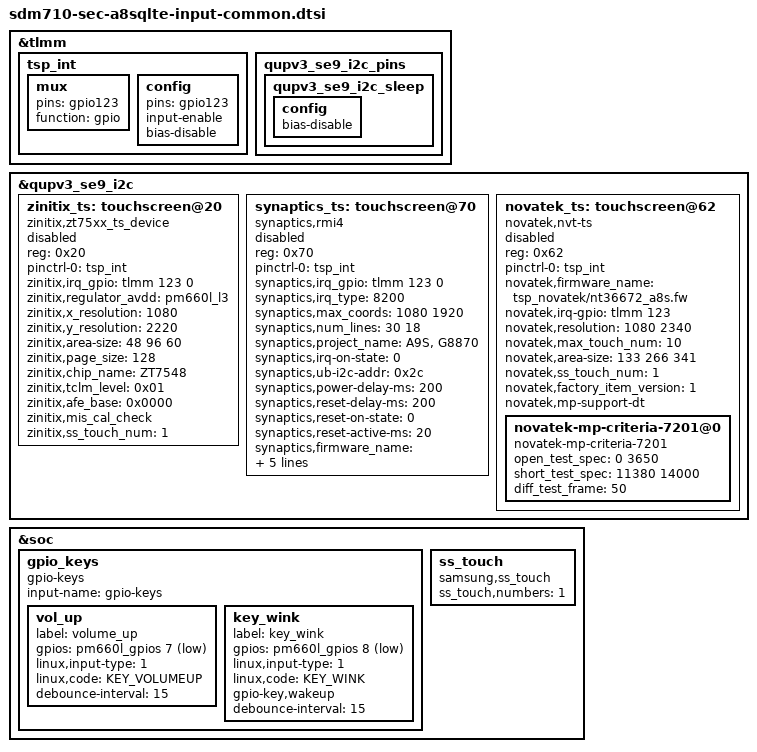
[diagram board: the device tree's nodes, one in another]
/* Copyright (c) 2016-2017, The Linux Foundation. All rights reserved.
 *
 * This program is free software; you can redistribute it and/or modify
 * it under the terms of the GNU General Public License version 2 and
 * only version 2 as published by the Free Software Foundation.
 *
 * This program is distributed in the hope that it will be useful,
 * but WITHOUT ANY WARRANTY; without even the implied warranty of
 * MERCHANTABILITY or FITNESS FOR A PARTICULAR PURPOSE.  See the
 * GNU General Public License for more details.
 */

#include <dt-bindings/input/input.h>

&tlmm {
	tsp_int: tsp_int {
		mux {
			pins = "gpio123";
			function = "gpio";
		};

		config {
			pins = "gpio123";
			input-enable;
			bias-disable;
		};
	};

	qupv3_se9_i2c_pins {
		qupv3_se9_i2c_sleep {
			config {
				/delete-property/bias-pull-up;
				bias-disable;
			};
		};
	};
};

&qupv3_se9_i2c {
	status = "ok";

	zinitix_ts: touchscreen@20 {
		status = "disabled";
		compatible = "zinitix,zt75xx_ts_device";
		reg = <0x20>;
		pinctrl-names = "default";
		pinctrl-0 = <&tsp_int>;
		zinitix,irq_gpio = <&tlmm 123 0>;
	/*	zinitix,gpio_ldo_en;*/
	/*	zinitix,regulator_dvdd = "s2mpb02_sub-ldo5";*/
		zinitix,regulator_avdd = "pm660l_l3";
		zinitix,x_resolution = <1080>;
		zinitix,y_resolution = <2220>;
		zinitix,area-size = <48 96 60>; /* indicator: 24dp navigator:48dp edge:60px dpi=320 */
		zinitix,page_size = <128>;
		zinitix,chip_name = "ZT7548";
	/*	zinitix,firmware_name = "tsp_zinitix/zt7548_astar.fw"; */
	/*	zinitix,spay;*/
	/*	zinitix,aod;*/
		zinitix,tclm_level = <0x01>;
		zinitix,afe_base = <0x0000>;
		zinitix,mis_cal_check;
	/*	zinitix,factory_item_version = <4>;*/
		zinitix,ss_touch_num = <1>;
	};

	synaptics_ts: touchscreen@70 {
		status = "disabled";
		compatible = "synaptics,rmi4";
		reg = <0x70>;
		pinctrl-names = "default";
		pinctrl-0 = <&tsp_int>;
		synaptics,irq_gpio = <&tlmm 123 0>;
		synaptics,irq_type = <8200>;
		synaptics,max_coords = <1080 1920>;	/* x y */
		synaptics,num_lines = <30 18>;		/* rx tx */
		synaptics,project_name = "A9S","G8870";
		synaptics,irq-on-state = <0>;
		synaptics,ub-i2c-addr = <0x2c>;
		synaptics,power-delay-ms = <200>;
		synaptics,reset-delay-ms = <200>;
		synaptics,reset-on-state = <0>;
		synaptics,reset-active-ms = <20>;
		synaptics,firmware_name = "tsp_synaptics/td4300_on7xelte.fw";
		synaptics,firmware_name_bl = "tsp_synaptics/td4300_on7xelte_recovery.fw";
		synaptics,ss_touch_num = <1>;
		synaptics,bringup;
	};

	novatek_ts: touchscreen@62 {
		status = "disabled";
		compatible = "novatek,nvt-ts";
		reg = <0x62>;
		pinctrl-names = "default";
		pinctrl-0 = <&tsp_int>;
		novatek,firmware_name = "tsp_novatek/nt36672_a8s.fw";
		novatek,irq-gpio = <&tlmm 123 0x2002>;
		novatek,resolution = <1080 2340>; /* x y */
		novatek,max_touch_num = <10>;
		novatek,area-size = <133 266 341>; /* indicator: 24dp navigator: 48dp edge: 60px dpi=320 */
		novatek,ss_touch_num = <1>;
		novatek,factory_item_version = <1>;

		novatek,mp-support-dt;

		novatek-mp-criteria-7201@0 {
			#address-cells = <1>;
			#size-cells = <0>;
			compatible = "novatek-mp-criteria-7201";

			/* MP Criteria */
			open_test_spec = <0 3650>;
			short_test_spec = <11380 14000>;

			diff_test_frame = <50>;
		};
	};
};

&soc {
	/delete-node/gpio_keys;
	gpio_keys {
		status = "ok";
		compatible = "gpio-keys";
		input-name = "gpio-keys";

		vol_up {
			label = "volume_up";
			gpios = <&pm660l_gpios 7 0x1>;	/* VOL_UP */
			linux,input-type = <1>;
			linux,code = <KEY_VOLUMEUP>;
			debounce-interval = <15>;
		};

		key_wink {
			label = "key_wink";
			gpios = <&pm660l_gpios 8 0x1>;
			linux,input-type = <1>;
			linux,code = <KEY_WINK>;
			gpio-key,wakeup;
			debounce-interval = <15>;
		};
	};

	ss_touch {
		compatible = "samsung,ss_touch";
		ss_touch,numbers = <1>;
	};
};
